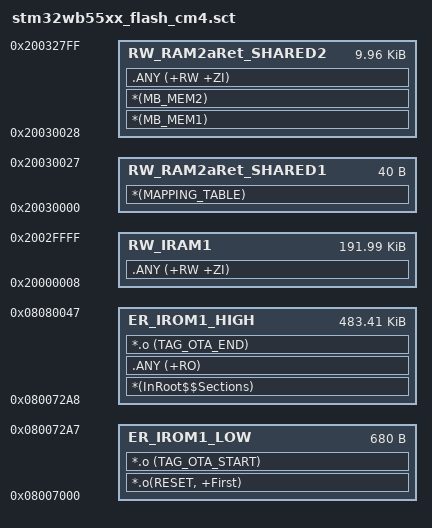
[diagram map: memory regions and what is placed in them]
; *************************************************************
; *** Scatter-Loading Description File generated by uVision ***
; *************************************************************

LR_IROM1 0x08007000 0x2A8 {    ; load region size_region
  ER_IROM1_LOW 0x08007000 0x2A8  {  ; load address = execution address
 *.o(RESET, +First)
 *.o (TAG_OTA_START) 
  }
 
  RW_IRAM1 0x20000008 0x0002FFF8  {  ; RW data
    .ANY (+RW +ZI)
  }

   RW_RAM2aRet_SHARED1 0x20030000 0x28  {  ; RW data 
      *(MAPPING_TABLE)
   }
   RW_RAM2aRet_SHARED2 0x20030028 0x27D8  { ; RW data      
    *(MB_MEM1)
    *(MB_MEM2)
    .ANY (+RW +ZI)
   }
}

LR_IROM3 0x080072A8 0x78DA0 {
  ER_IROM1_HIGH 0x080072A8 0x78DA0 {  ; load address = execution address	
	*(InRoot$$Sections)
	.ANY (+RO)  
	*.o (TAG_OTA_END)	
  }
  }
